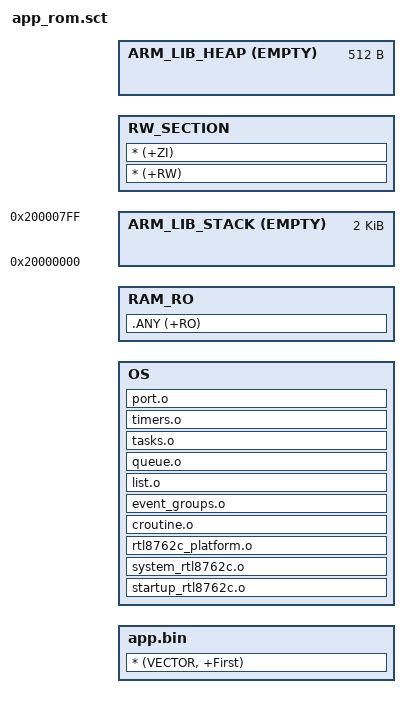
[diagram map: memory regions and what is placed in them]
#!armclang --target=arm-arm-none-eabi -march=armv8-m.main -E -x c
#include "..\src\peripheral\bb2ultra_rom_defines.h"
#include "..\src\peripheral\mem_config.h"
; *************************************************************
; *** Scatter-Loading Description File generated by uVision ***
; *************************************************************

;LOAD_BUFFER_RAM EXT0_ADDR EXT0_SIZE
;{
;    TEST_BUFFER_DATA +0
;    {
;        * (.ram.buffer)
;    }
;}

;LOAD_DATA_RAM1 DATA_SRAM1_ADDR DATA_SRAM1_SIZE
;{

;    TEST_DATA_RAM1 +0
;    {
;        * (.ram.data1)
;    }

;}

;LOAD_DATA_RAM0 DATA_SRAM0_ADDR DATA_SRAM0_SIZE
;{

;    TEST_DATA_RAM0 +0
;    {
;        * (.ram.data0)
;    }
;}

LOAD_ITCM0 CM33_ROM_BASE TOTAL_ROM_SIZE
{   

    app.bin +0
    {
        * (VECTOR, +First)
;        * (RESET)
;        * (InRoot$$Sections)
	}	
	
    OS  +0
    {
        startup_rtl8762c.o
        system_rtl8762c.o
        rtl8762c_platform.o
        croutine.o
        event_groups.o
        list.o
        queue.o
        tasks.o
        timers.o
        port.o
    }
    
    RAM_RO +0
    {
        .ANY (+RO)   
    }
;    TEST_DATA_RAM +0
;    {
;        * (.ram.data)
;    }
;	
	ARM_LIB_STACK 0x20000000 ALIGN 8 EMPTY 0x800 {}
	  RW_SECTION +0
    {
        * (+RW)
        * (+ZI)
    }
	ARM_LIB_HEAP +0 ALIGN 8 EMPTY 0x200 {}
}

;LOAD_DTCM1 DTCM1_RAM_TEXT_ADR DTCM1_RAM_TEXT_SIZE
;{
;    RAM_RO1.bin +0
;    {
;        .ANY (+RO)   
;    }
;}

;LOAD_SHARE_RAM DSP_SHM_ADDR DSP_SHM_SIZE
;{
;    TEST_SHARE_DATA +0
;    {
;        * (.ram.share.data)
;    }
;}


